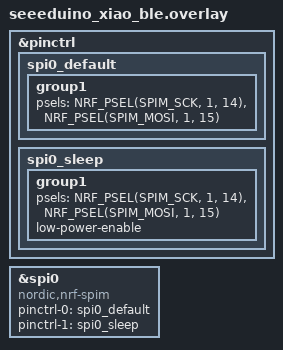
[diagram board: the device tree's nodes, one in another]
&pinctrl {
    spi0_default: spi0_default {
        group1 {
            psels =
                <NRF_PSEL(SPIM_SCK, 1, 14)>, //P1.14 D9
                <NRF_PSEL(SPIM_MOSI, 1, 15)>; //P1.15 D10
        };
    };
    spi0_sleep: spi0_sleep {
        group1 {
            psels =
                <NRF_PSEL(SPIM_SCK, 1, 14)>, //P1.14 D9
                <NRF_PSEL(SPIM_MOSI, 1, 15)>; //P1.15 D10
            low-power-enable;
        };
    };
};

&spi0 {
    compatible = "nordic,nrf-spim";
    pinctrl-0 = <&spi0_default>;
    pinctrl-1 = <&spi0_sleep>;
    pinctrl-names = "default", "sleep";
};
